# USCI_A0__UART_Mode_3 register map
Vendor: Texas Instruments
Peripheral module from a debugger description file (folder msp430).
Registers are 16-bit, access not given, no defined reset value unless marked. A register's access mark holds for its fields unless they carry their own. Offsets are as the file gives them; lines under a group give offsets from that group; [hi:lo] are bit positions; {n}, {i} and the like mark numbered series; 'fields as' and 'values as' point back to an identical list; <NAME> marks a mode.

## USCI_A0_UART_Mode
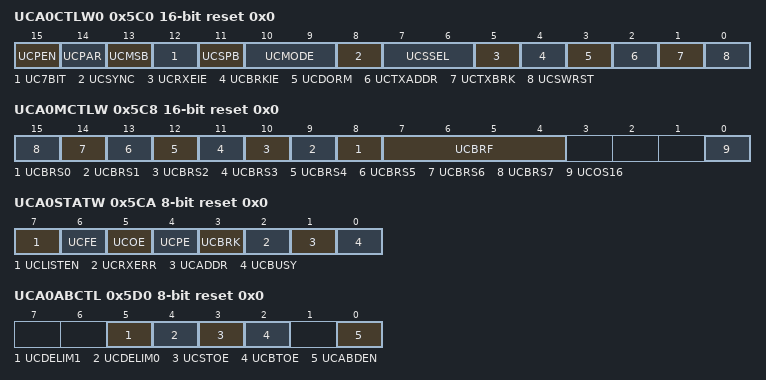
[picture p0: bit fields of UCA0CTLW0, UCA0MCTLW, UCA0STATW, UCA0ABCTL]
0x5C0 UCA0CTLW0 rw reset 0x0 — USCI A0 Control Word Register 0
  [15] UCPEN — Async. Mode: Parity enable
  [14] UCPAR — Async. Mode: Parity 0:odd / 1:even
  [13] UCMSB — Async. Mode: MSB first 0:LSB / 1:MSB
  [12] UC7BIT — Async. Mode: Data Bits 0:8-bits / 1:7-bits
  [11] UCSPB — Async. Mode: Stop Bits 0:one / 1: two
  [10:9] UCMODE — Async. Mode: USCI Mode 1
    {v}=Sync. Mode: USCI Mode: {v} (v=0..3)
  [8] UCSYNC — Sync-Mode 0:UART-Mode / 1:SPI-Mode
  [7:6] UCSSEL — USCI 0 Clock Source Select 1
    {v}=USCI 0 Clock Source: {v} (v=0..3)
  [5] UCRXEIE — RX Error interrupt enable
  [4] UCBRKIE — Break interrupt enable
  [3] UCDORM — Dormant (Sleep) Mode
  [2] UCTXADDR — Send next Data as Address
  [1] UCTXBRK — Send next Data as Break
  [0] UCSWRST — USCI Software Reset
0x5C0 UCA0CTL1 8-bit — USCI A0 Control Register 1
0x5C1 UCA0CTL0 8-bit — USCI A0 Control Register 0
0x5C2 UCA0CTLW1 rw reset 0x0 — USCI A0 Control Word Register 1
  [1:0] UCGLIT — USCI Deglitch Time Bit 1
    {v}=USCI Deglitch time: {v} (v=0..3)
0x5C6 UCA0BRW — USCI A0 Baud Word Rate 0
0x5C6 UCA0BR0 8-bit — USCI A0 Baud Rate 0
0x5C7 UCA0BR1 8-bit — USCI A0 Baud Rate 1
0x5C8 UCA0MCTLW rw reset 0x0 — USCI A0 Modulation Control
  [n+8] UCBRS{n} (n=0..7) — USCI Second Stage Modulation Select {n}
  [7:4] UCBRF — USCI First Stage Modulation Select 3
    {v}=USCI First Stage Modulation: {v} (v=0..9); 10=USCI First Stage Modulation: A; 11=USCI First Stage Modulation: B; 12=USCI First Stage Modulation: C; 13=USCI First Stage Modulation: D; 14=USCI First Stage Modulation: E; 15=USCI First Stage Modulation: F
  [0] UCOS16 — USCI 16-times Oversampling enable
0x5CA UCA0STATW 8-bit rw reset 0x0 — USCI A0 Status Register
  [7] UCLISTEN — USCI Listen mode
  [6] UCFE — USCI Frame Error Flag
  [5] UCOE — USCI Overrun Error Flag
  [4] UCPE — USCI Parity Error Flag
  [3] UCBRK — USCI Break received
  [2] UCRXERR — USCI RX Error Flag
  [1] UCADDR — USCI Address received Flag
  [0] UCBUSY — USCI Busy Flag
0x5CC UCA0RXBUF — USCI A0 Receive Buffer
0x5CE UCA0TXBUF — USCI A0 Transmit Buffer
0x5D0 UCA0ABCTL 8-bit rw reset 0x0 — USCI A0 LIN Control
  [5] UCDELIM1 — Break Sync Delimiter 1
  [4] UCDELIM0 — Break Sync Delimiter 0
  [3] UCSTOE — Sync-Field Timeout error
  [2] UCBTOE — Break Timeout error
  [0] UCABDEN — Auto Baud Rate detect enable
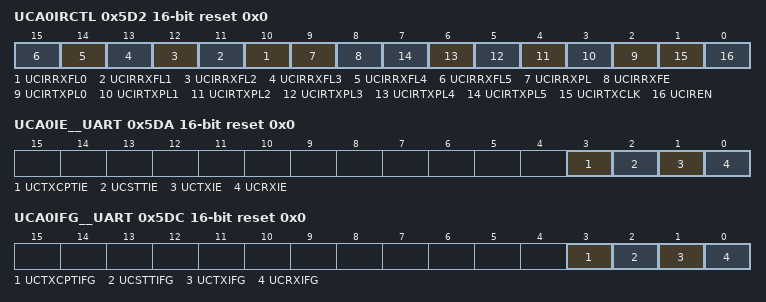
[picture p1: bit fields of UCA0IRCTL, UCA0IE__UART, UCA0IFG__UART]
0x5D2 UCA0IRCTL rw reset 0x0 — USCI A0 IrDA Transmit Control
  [n+10] UCIRRXFL{n} (n=0..5) — IRDA Receive Filter Length {n}
  [9] UCIRRXPL — IRDA Receive Input Polarity
  [8] UCIRRXFE — IRDA Receive Filter enable
  [n+2] UCIRTXPL{n} (n=0..5) — IRDA Transmit Pulse Length {n}
  [1] UCIRTXCLK — IRDA Transmit Pulse Clock Select
  [0] UCIREN — IRDA Encoder/Decoder enable
0x5D2 UCA0IRTCTL 8-bit — USCI A0 IrDA Transmit Control
0x5D3 UCA0IRRCTL 8-bit — USCI A0 IrDA Receive Control
0x5DA UCA0IE — USCI A0 Interrupt Enable Register
0x5DA UCA0IE__UART rw reset 0x0 — USCI A0 Interrupt Enable Register
  [3] UCTXCPTIE — UART Transmit Complete Interrupt Enable
  [2] UCSTTIE — UART Start Bit Interrupt Enalble
  [1] UCTXIE — UART Transmit Interrupt Enable
  [0] UCRXIE — UART Receive Interrupt Enable
0x5DC UCA0IFG — USCI A0 Interrupt Flags Register
0x5DC UCA0IFG__UART rw reset 0x0 — USCI A0 Interrupt Flags Register
  [3] UCTXCPTIFG — UART Transmit Complete Interrupt Flag
  [2] UCSTTIFG — UART Start Bit Interrupt Flag
  [1] UCTXIFG — UART Transmit Interrupt Flag
  [0] UCRXIFG — UART Receive Interrupt Flag
0x5DE UCA0IV — USCI A0 Interrupt Vector Register
